# RN831X_RN861X_MCU register map
File version: v0.0.1
CPU: RN831X_RN861X_MCU r1p0, little endian, MPU, no FPU
Registers are 32-bit, read-write, reset 0x0 unless marked. A register's access mark holds for its fields unless they carry their own. Offsets are from the block's base; [hi:lo] are bit positions; {n}, {i} and the like mark numbered series; 'fields as' and 'values as' point back to an identical list.

## DMA00 — General Driect Memory Access module
Base 0x20104000
Same registers: DMA01 0x20108000, DMA10 0xA0104000, DMA11 0xA0108000
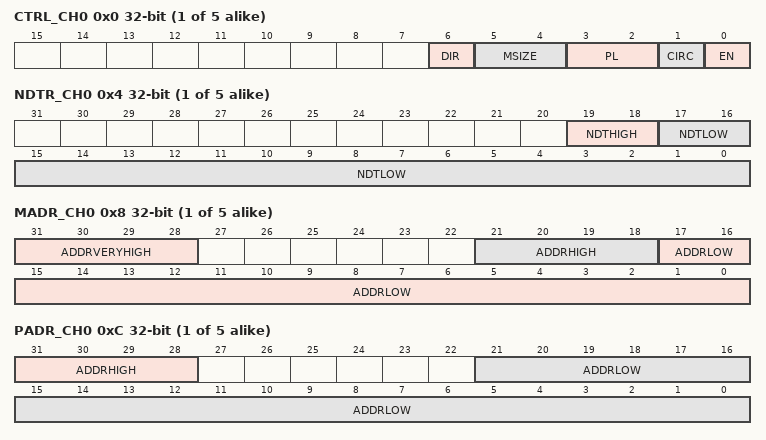
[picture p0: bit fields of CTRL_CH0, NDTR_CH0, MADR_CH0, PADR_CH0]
{0x0+0x20*i} CTRL_CH{i} (i=0..4) — DMA Control Register for channel {i}.
  [6] DIR — Configure the DMA transmission direction.
  [5:4] MSIZE — Configure the data size of DMA for a single transaction.
    0=BYTE (Data is transferred in byte.); 1=HWORD (Data is transferred in half-word.); 2=WORD (Data is transferred in word.)
  [3:2] PL — Configure the DMA channel priority.
    0=LOW (Set the channel priority to the lowest.); 1=MEDIUM (Set the channel priority to medium.); 2=HIGH (Set the channel priority to high.); 3=VERYHIGH (Set the channel priority to the highest.)
  [1] CIRC — Enable DMA circle mode.
  [0] EN — Enable DMA to start data migration.
{0x4+0x20*i} NDTR_CH{i} (i=0..4) — DMA Data Length Register for channel {i}.
  [19:18] NDTHIGH — when current channel could access Flash.
  [17:0] NDTLOW — when current channel could not access Flash.
{0x8+0x20*i} MADR_CH{i} (i=0..4) — DMA Memory Address Register for channel {i}.
  [31:28] ADDRVERYHIGH — default valid bit field.
  [21:18] ADDRHIGH — when current channel could access Flash.
  [17:0] ADDRLOW — when current channel could not access Flash.
{0xC+0x20*i} PADR_CH{i} (i=0..4) — DMA Peripheral-side Address Register for channel {i}.
  [31:28] ADDRHIGH — default valid bit field.
  [21:0] ADDRLOW — default valid bit field.
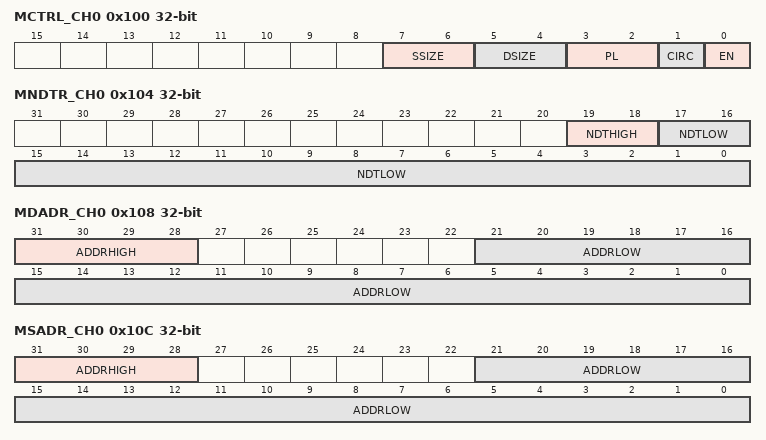
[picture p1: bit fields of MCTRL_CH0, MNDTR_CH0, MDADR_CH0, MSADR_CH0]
0x100 MCTRL_CH0 — DMA Control Register for M2M channel 0.
  [7:6] SSIZE — Configure the source port data size of DMA for a single transaction
  [5:4] DSIZE — Configure the dest port data size of DMA for a single transaction
    0=BYTE (Data is transferred in byte); 1=HWORD (Data is transferred in half-word); 2=WORD (Data is transferred in word)
  [3:2] PL — Configure the DMA channel priority
    0=LOW (Set the channel priority to the lowest); 1=MEDIUM (Set the channel priority to medium); 2=HIGH (Set the channel priority to high); 3=VERYHIGH (Set the channel priority to the highest)
  [1] CIRC — Enable DMA circle mode
  [0] EN — Enable DMA to start data migration
0x104 MNDTR_CH0 — DMA Data Length Register for M2M channel 0.
  fields as NDTR_CH0
0x108 MDADR_CH0 — DMA M2M Channel Destination Register for M2M channel 0.
  fields as PADR_CH0
0x10C MSADR_CH0 — DMA M2M Channel Source Address Register for M2M channel 0.
  fields as PADR_CH0
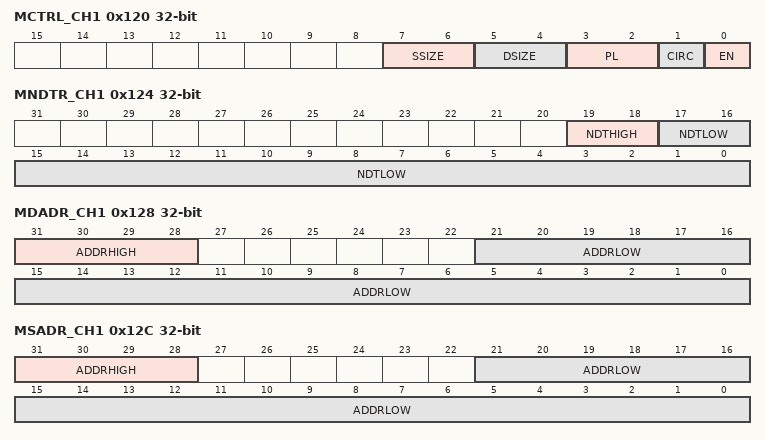
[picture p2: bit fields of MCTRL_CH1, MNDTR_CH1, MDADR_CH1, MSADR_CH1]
0x120 MCTRL_CH1 — DMA Control Register for M2M channel 1.
  fields as MCTRL_CH0
0x124 MNDTR_CH1 — DMA Data Length Register for M2M channel 1.
  fields as NDTR_CH0
0x128 MDADR_CH1 — DMA M2M Channel Destination Register for M2M channel 1.
  fields as PADR_CH0
0x12C MSADR_CH1 — DMA M2M Channel Source Address Register for M2M channel 1.
  fields as PADR_CH0
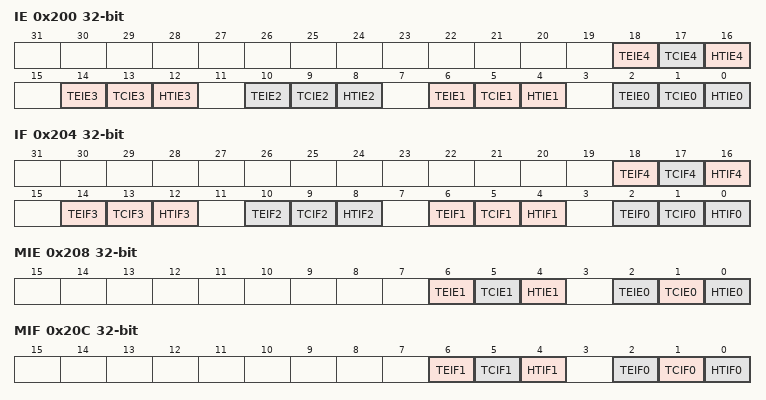
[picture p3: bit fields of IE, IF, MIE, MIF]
0x200 IE — DMA Normal Channel Interrupt Enable Register.
  [18] TEIE4 — Enable channel 4 transfer error interrupt, only valid in DMAx0.
  [17] TCIE4 — Enable channel 4 transfer complete interrupt, only valid in DMAx0.
  [16] HTIE4 — Enable channel 4 transfer half interrupt, only valid in DMAx0.
  [4n+2] TEIE{n} (n=0..3) — Enable channel {n} transfer error interrupt.
  [4n+1] TCIE{n} (n=0..3) — Enable channel {n} transfer complete interrupt.
  [4n] HTIE{n} (n=0..3) — Enable channel {n} transfer half interrupt.
0x204 IF — DMA Normal Channel Interrupt Flags Register.
  [18] TEIF4 write-1-clears — Check channel 4 transfer error interrupt flag is actived, only valid in DMAx0.
  [17] TCIF4 write-1-clears — Check channel 4 transfer complete interrupt flag is actived, only valid in DMAx0.
  [16] HTIF4 write-1-clears — Check channel 4 transfer half interrupt flag is actived, only valid in DMAx0.
  [4n+2] TEIF{n} write-1-clears (n=0..3) — Check channel {n} transfer error interrupt flag is actived.
  [4n+1] TCIF{n} write-1-clears (n=0..3) — Check channel {n} transfer complete interrupt flag is actived.
  [4n] HTIF{n} write-1-clears (n=0..3) — Check channel {n} transfer half interrupt flag is actived.
0x208 MIE — DMA M2M Channel Interrupt Enable Register.
  [6] TEIE1 — Enable M2M channel 1 transfer error interrupt.
  [5] TCIE1 — Enable M2M channel 1 transfer complete interrupt.
  [4] HTIE1 — Enable M2M channel 1 transfer half interrupt.
  [2] TEIE0 — Enable M2M channel 0 transfer error interrupt.
  [1] TCIE0 — Enable M2M channel 0 transfer complete interrupt.
  [0] HTIE0 — Enable M2M channel 0 transfer half interrupt.
0x20C MIF — DMA M2M Channel Interrupt Flags Register.
  [6] TEIF1 write-1-clears — Check M2M channel 1 tansfer error interrupt flag is actived.
  [5] TCIF1 write-1-clears — Check M2M channel 1 tansfer complete interrupt flag is actived.
  [4] HTIF1 write-1-clears — Check M2M channel 1 tansfer half interrupt flag is actived.
  [2] TEIF0 write-1-clears — Check M2M channel 0 tansfer error interrupt flag is actived.
  [1] TCIF0 write-1-clears — Check M2M channel 0 tansfer complete interrupt flag is actived.
  [0] HTIF0 write-1-clears — Check M2M channel 0 tansfer half interrupt flag is actived.
